AUTOSAR XML (schema 4-0-3)
package /ComponentTypes
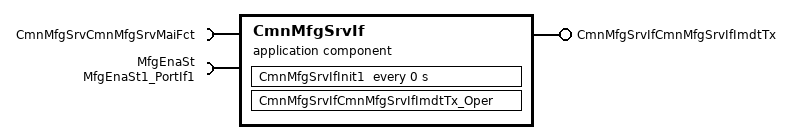
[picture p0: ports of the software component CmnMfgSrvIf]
  application sw component type CmnMfgSrvIf
    provide port CmnMfgSrvIfCmnMfgSrvIfImdtTx: server-com-spec{operation=Oper, queue-length=1}, provided-interface=CmnMfgSrvIfCmnMfgSrvIfImdtTx
    require port CmnMfgSrvCmnMfgSrvMaiFct: required-interface=CmnMfgSrvCmnMfgSrvMaiFct
    require port MfgEnaSt: nonqueued-receiver-com-spec{data-element=Val, filter=data-filter-type=ALWAYS, init-value=0}, required-interface=MfgEnaSt1_PortIf1
    behavior CmnMfgSrvIf_InternalBehavior
      ar-typed-per-instance-memorys:
        data CmnMfgSrvUnlckd: sw-calibration-access=READ-ONLY, type=boolean
        data DataBuf: sw-calibration-access=READ-ONLY, type=Ary1D_u8_CmnMfgSrvIf
      operation invoked event OIT_CmnMfgSrvIfCmnMfgSrvIfImdtTx_Oper_CmnMfgSrvIfCmnMfgSrvIfImdtTx_Oper: start-on-event=CmnMfgSrvIfCmnMfgSrvIfImdtTx_Oper, operation=CmnMfgSrvIfCmnMfgSrvIfImdtTx.Oper
      timing event CmnMfgSrvIf_InitEvent: start-on-event=CmnMfgSrvIfInit1, period=0
      runnable CmnMfgSrvIfCmnMfgSrvIfImdtTx_Oper
      runnable CmnMfgSrvIfInit1
        data-receive-point-by-arguments:
          access REC_MfgEnaSt_Val: accessed-variable=MfgEnaSt.Val
        sync call SC_CmnMfgSrvCmnMfgSrvMaiFct_Oper: operation=CmnMfgSrvCmnMfgSrvMaiFct.Oper, timeout=0
  swc implementation CmnMfgSrvIf_Implementation: behavior=CmnMfgSrvIf_InternalBehavior
    code-descriptors:
      code Default: artifact-descriptors=autosar-engineering-object={short-label=Default, category=SWSRC}
